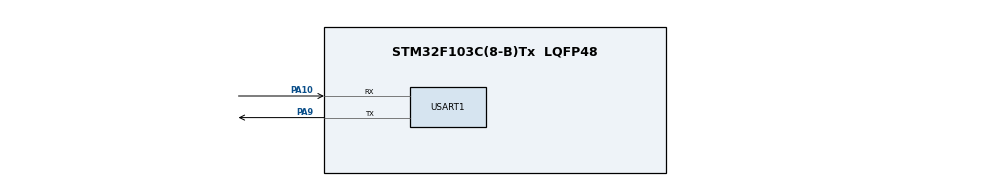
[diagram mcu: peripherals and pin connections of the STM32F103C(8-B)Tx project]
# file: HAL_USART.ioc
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Mcu.Family=STM32F1
Mcu.Name=STM32F103C(8-B)Tx
Mcu.Package=LQFP48
NVIC.PriorityGroup=NVIC_PRIORITYGROUP_4
PA10.Mode=Asynchronous
PA10.Signal=USART1_RX
PA13.Mode=Serial_Wire
PA13.Signal=SYS_JTMS-SWDIO
PA14.Mode=Serial_Wire
PA14.Signal=SYS_JTCK-SWCLK
PA9.Mode=Asynchronous
PA9.Signal=USART1_TX
ProjectManager.HeapSize=0x200
ProjectManager.StackSize=0x400
ProjectManager.TargetToolchain=MDK-ARM V5.32
RCC.APB1Freq_Value=8000000
RCC.APB2Freq_Value=8000000
USART1.VirtualMode=VM_ASYNC
USART1.WordLength=WORDLENGTH_8B
board=custom

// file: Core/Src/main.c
/* USER CODE BEGIN Header */
/**
 ******************************************************************************
 * @file           : main.c
 * @brief          : Main program body
 ******************************************************************************
 * @attention
 *
 * Copyright (c) 2026 STMicroelectronics.
 * All rights reserved.
 *
 * This software is licensed under terms that can be found in the LICENSE file
 * in the root directory of this software component.
 * If no LICENSE file comes with this software, it is provided AS-IS.
 *
 ******************************************************************************
 */
/* USER CODE END Header */
#include "main.h"

/* USER CODE BEGIN Includes */
#include <string.h>
/* USER CODE END Includes */

UART_HandleTypeDef huart1;

/* USER CODE BEGIN PV */
/**
 * @brief 待发送的数据示例
 *
 * 以下四种变量覆盖了 HAL_UART_Transmit() 最常见的调用场景：
 *  - 单字节发送        ：byteNumber
 *  - 定长字节数组发送  ：byteArray
 *  - 单字符发送        ：ch
 *  - 字符串发送        ：str
 */
uint8_t byteNumber = 0x5a;          /* 单个字节数据（十六进制） */
uint8_t byteArray[] = {1,2,3,4,5};  /* 定长字节数组，共 5 个字节 */
char ch = 'a';                      /* 单个字符，'a' 的 ASCII 码为 0x61 */
char *str = "Hello world";          /* 字符串，以 '\0' 结尾，共 11 个字符 */
/* USER CODE END PV */

void SystemClock_Config(void);
static void MX_GPIO_Init(void);
static void MX_USART1_UART_Init(void);

int main(void)
{

  /* MCU Configuration--------------------------------------------------------*/

  /* Reset of all peripherals, Initializes the Flash interface and the Systick. */
  HAL_Init();

  /* Configure the system clock */
  SystemClock_Config();

  /* Initialize all configured peripherals */
  MX_GPIO_Init();
  MX_USART1_UART_Init();

  /* Infinite loop */
  while (1)
  {

    /* USER CODE BEGIN 3 */
    /**
     * @brief 通过 USART1 依次发送四种类型的数据
     *
     * HAL_UART_Transmit() 函数原型：
     *   HAL_StatusTypeDef HAL_UART_Transmit(
     *       UART_HandleTypeDef *huart,   // 串口句柄，指定使用哪个串口
     *       uint8_t *pData,              // 待发送数据的首地址
     *       uint16_t Size,               // 要发送的字节数
     *       uint32_t Timeout             // 超时时间，HAL_MAX_DELAY 表示永远等待
     *   );
     */
    // 场景1：发送单字节数据 0x5A（&byteNumber 取出其地址）
    HAL_UART_Transmit(&huart1, &byteNumber, 1, HAL_MAX_DELAY);

    // 场景2：发送定长字节数组 {1,2,3,4,5}，共 5 个字节
    //        数组名 byteArray 本身就是首地址，可直接作为 pData 传入
    HAL_UART_Transmit(&huart1, byteArray, 5, HAL_MAX_DELAY);

    // 场景3：发送单个字符 'a'（ASCII 码 0x61）
    //        ch 是 char 类型，需强制转换为 uint8_t* 才能匹配函数形参类型
    HAL_UART_Transmit(&huart1, (uint8_t *)&ch, 1, HAL_MAX_DELAY);

    // 场景4：发送字符串 "Hello world"（不含结尾的 '\0'）
    //        strlen(str) 计算出有效字符个数 = 11
    HAL_UART_Transmit(&huart1, (uint8_t *)str, strlen(str), HAL_MAX_DELAY);

    // 延时 1 秒，让上述 4 次发送数据在串口助手中分组成批地显示，便于观察
    HAL_Delay(1000);
  }
  /* USER CODE END 3 */
}

void SystemClock_Config(void)
{
  RCC_OscInitTypeDef RCC_OscInitStruct = {0};
  RCC_ClkInitTypeDef RCC_ClkInitStruct = {0};

  /** Initializes the RCC Oscillators according to the specified parameters
   * in the RCC_OscInitTypeDef structure.
   */
  RCC_OscInitStruct.OscillatorType = RCC_OSCILLATORTYPE_HSI;
  RCC_OscInitStruct.HSIState = RCC_HSI_ON;
  RCC_OscInitStruct.HSICalibrationValue = RCC_HSICALIBRATION_DEFAULT;
  RCC_OscInitStruct.PLL.PLLState = RCC_PLL_NONE;
  if (HAL_RCC_OscConfig(&RCC_OscInitStruct) != HAL_OK)
  {
    Error_Handler();
  }

  /** Initializes the CPU, AHB and APB buses clocks
   */
  RCC_ClkInitStruct.ClockType = RCC_CLOCKTYPE_HCLK | RCC_CLOCKTYPE_SYSCLK | RCC_CLOCKTYPE_PCLK1 | RCC_CLOCKTYPE_PCLK2;
  RCC_ClkInitStruct.SYSCLKSource = RCC_SYSCLKSOURCE_HSI;
  RCC_ClkInitStruct.AHBCLKDivider = RCC_SYSCLK_DIV1;
  RCC_ClkInitStruct.APB1CLKDivider = RCC_HCLK_DIV1;
  RCC_ClkInitStruct.APB2CLKDivider = RCC_HCLK_DIV1;

  if (HAL_RCC_ClockConfig(&RCC_ClkInitStruct, FLASH_LATENCY_0) != HAL_OK)
  {
    Error_Handler();
  }
}

static void MX_USART1_UART_Init(void)
{

  huart1.Instance = USART1;
  huart1.Init.BaudRate = 115200;
  huart1.Init.WordLength = UART_WORDLENGTH_8B;   /* 数据位 8 位 */
  huart1.Init.StopBits = UART_STOPBITS_1;
  huart1.Init.Parity = UART_PARITY_NONE;
  huart1.Init.Mode = UART_MODE_TX_RX;
  huart1.Init.HwFlowCtl = UART_HWCONTROL_NONE;
  huart1.Init.OverSampling = UART_OVERSAMPLING_16;
  if (HAL_UART_Init(&huart1) != HAL_OK)
  {
    Error_Handler();
  }
}

static void MX_GPIO_Init(void)
{

  /* GPIO Ports Clock Enable */
  __HAL_RCC_GPIOA_CLK_ENABLE();

}

void Error_Handler(void)
{
  __disable_irq();
  while (1)
  {
  }
}
